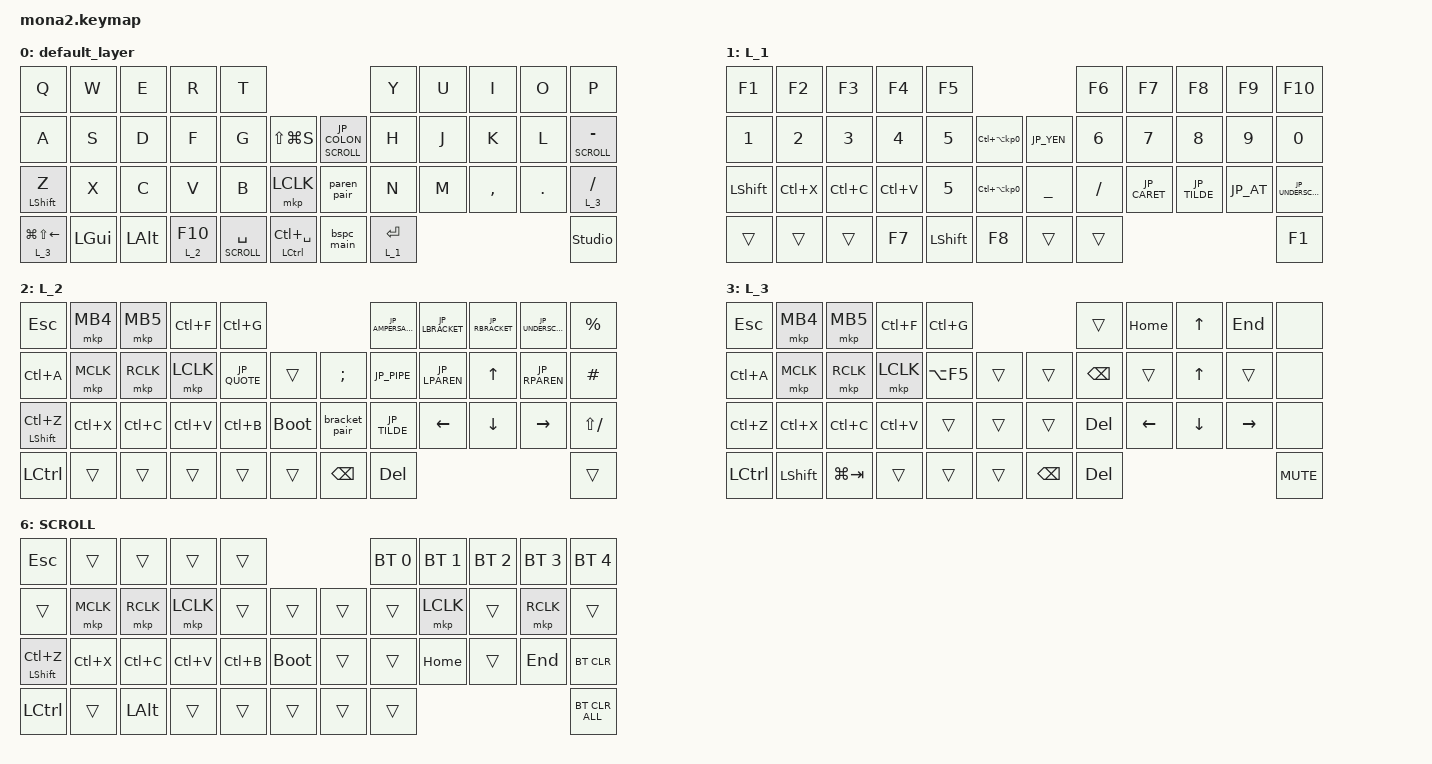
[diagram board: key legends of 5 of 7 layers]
#include <behaviors.dtsi>
#include <dt-bindings/zmk/bt.h>
#include <dt-bindings/zmk/keys.h>
#include <dt-bindings/zmk/pointing.h>
#include <dt-bindings/zmk/input_transform.h>
//#include <dt-bindings/zmk/studio_unlock.h>

/* レイヤー番号の定義：&lt や &mo で使う名前を数値に紐付けます */
#define L_BASE 0
#define L_1    1
#define L_2    2
#define L_3    3
#define L_4    4
#define MOUSE  5
#define SCROLL 6

// --- 日本語キーボード用の定義（全角スペース等のゴミを除去） ---
#define JP_DQUOTE      AT
#define JP_AMPERSAND   CARET
#define JP_QUOTE       AMPERSAND
#define JP_EQUAL       UNDER
#define JP_CARET       EQUAL
#define JP_YEN         0x89
#define JP_PLUS        COLON
#define JP_TILDE       PLUS
#define JP_PIPE        LS(0x89)
#define JP_AT          LEFT_BRACKET
#define JP_COLON       SINGLE_QUOTE
#define JP_ASTERISK    DOUBLE_QUOTES
#define JP_UNDERSCORE  LS(0x87)
#define JP_GRAVE       LS(LEFT_BRACE)
#define JP_LBRACKET    RIGHT_BRACKET
#define JP_RBRACKET    BACKSLASH
#define JP_LPAREN      ASTERISK
#define JP_RPAREN      LEFT_PARENTHESIS
#define JP_LBRACE      RIGHT_BRACE
#define JP_RBRACE      PIPE

&mt {
    flavor = "balanced";
    quick-tap-ms = <0>;
};

&lt {
    quick-tap-ms = <200>;
    flavor = "balanced";
};

/ {
    combos {
        compatible = "zmk,combos";
        tab { bindings = <&kp TAB>; key-positions = <11 12>; };
        shift_tab { bindings = <&kp LS(TAB)>; key-positions = <12 13>; };
        esc { bindings = <&kp ESC>; key-positions = <0 1>; };
        double_quotation { bindings = <&kp DOUBLE_QUOTES>; key-positions = <20 21>; };
        eq { bindings = <&kp EQUAL>; key-positions = <24 25>; };
    };

    macros {
        to_layer_0: to_layer_0 {
            compatible = "zmk,behavior-macro-one-param";
            #binding-cells = <1>;
            bindings = <&to 0 &macro_param_1to1 &kp MACRO_PLACEHOLDER>;
            label = "TO_LAYER_0";
        };

        paren_pair: paren_pair {
            compatible = "zmk,behavior-macro";
            #binding-cells = <0>;
            bindings = <&macro_tap &kp LS(NUMBER_8) &kp LS(NUMBER_9) &kp LEFT>;
        };
        
        bracket_pair: bracket_pair {
            compatible = "zmk,behavior-macro";
            #binding-cells = <0>;
            bindings = <&macro_tap &kp JP_LBRACKET &kp JP_RBRACKET &kp LEFT>;
        };
    };

    behaviors {
        lt_to_layer_0: lt_to_layer_0 {
            compatible = "zmk,behavior-hold-tap";
            label = "LAYER_TAP_TO_0";
            bindings = <&mo>, <&to_layer_0>;
            #binding-cells = <2>;
            tapping-term-ms = <200>;
        };

        scroll_up_down: mouse_wheel_up_down {
            compatible = "zmk,behavior-sensor-rotate";
            #sensor-binding-cells = <0>;
            bindings = <&msc SCRL_DOWN>, <&msc SCRL_UP>;
            tap-ms = <20>;
        };

        scroll_right_left: mouse_wheel_right_left {
            compatible = "zmk,behavior-sensor-rotate";
            #sensor-binding-cells = <0>;
            bindings = <&msc SCRL_LEFT>, <&msc SCRL_RIGHT>;
            tap-ms = <20>;
        };

        // DYA Studio対応: ランタイム回転
        rsr_vol: rsr_vol {
            compatible = "zmk,behavior-sensor-rotate";
            #sensor-binding-cells = <0>;
            bindings = <&kp C_VOL_DN>, <&kp C_VOL_UP>;
            tap-ms = <20>;
        };

                // バックスペースのTap-Dance（最新仕様）
        bspc_main: bspc_main {
            compatible = "zmk,behavior-tap-dance";
            #binding-cells = <0>;
            tapping-term-ms = <170>;
            bindings = <&bspc_single LSHFT BSPC>, <&bspc_repeat_hold 0 BSPC>;
        };

        bspc_single: bspc_single {
            compatible = "zmk,behavior-hold-tap";
            #binding-cells = <2>;
            flavor = "tap-preferred";
            tapping-term-ms = <200>;
            quick-tap-ms = <125>;
            bindings = <&kp>, <&kp>;
        };

        bspc_repeat_hold: bspc_repeat_hold {
            compatible = "zmk,behavior-hold-tap";
            #binding-cells = <2>;
            flavor = "tap-preferred";
            tapping-term-ms = <30>;
            bindings = <&bspc_macro>, <&kp>;
        };

        bspc_macro: bspc_macro {
            compatible = "zmk,behavior-macro";
            #binding-cells = <0>;
            bindings = <&macro_press &kp BSPC>, <&macro_pause_for_release>, <&macro_release &kp BSPC>;
        };

    };

    keymap {
        compatible = "zmk,keymap";

        default_layer {
            bindings = <
&kp Q               &kp W            &kp E               &kp R               &kp T                                                                                                    &kp Y                   &kp U                   &kp I                &kp O            &kp P
&kp A               &kp S            &kp D               &kp F               &kp G                            &kp LS(LG(S))                &lt SCROLL JP_COLON                    &kp H                   &kp J                   &kp K                &kp L            &lt SCROLL MINUS
&mt LEFT_SHIFT Z    &kp X            &kp C               &kp V               &kp B                            &mkp LCLK                    &paren_pair                         &kp N                   &kp M                   &kp COMMA            &kp DOT          &lt L_3 SLASH
&lt L_3 LG(LS(LEFT_ARROW)) &kp LEFT_GUI &kp LEFT_ALT     &lt L_2 F10         &lt SCROLL SPACE           &mt LEFT_CONTROL LC(SPACE)  &bspc_main   &lt L_1 ENTER                                                                                                         &studio_unlock
        >;
            sensor-bindings = <&rsr_vol>;
        };

        L_1 {
            bindings = <
&kp F1                      &kp F2           &kp F3           &kp F4           &kp F5                                                      &kp F6        &kp F7             &kp F8          &kp F9           &kp F10
&kp NUMBER_1      &kp NUMBER_2     &kp NUMBER_3     &kp NUMBER_4     &kp NUMBER_5    &kp LC(LA(KP_NUMBER_0))      &kp JP_YEN  &kp NUMBER_6  &kp NUMBER_7       &kp NUMBER_8    &kp NUMBER_9     &kp NUMBER_0
&kp LEFT_SHIFT    &kp LC(X)        &kp LC(C)        &kp LC(V)        &kp NUMBER_5    &kp LC(LA(KP_NUMBER_0))      &kp UNDERSCORE  &kp SLASH  &kp JP_CARET       &kp JP_TILDE     &kp JP_AT       &kp JP_UNDERSCORE
&trans            &trans           &trans           &kp F7           &kp LEFT_SHIFT  &kp F8                       &trans             &trans                                                      &kp F1
            >;
            sensor-bindings = <&scroll_right_left>;
        };

        L_2 {
            bindings = <
&kp ESC                &mkp MB4        &mkp MB5          &kp LC(F)      &kp LC(G)                                     &kp JP_AMPERSAND  &kp JP_LBRACKET  &kp JP_RBRACKET  &kp JP_UNDERSCORE  &kp PERCENT
&kp LC(A)              &mkp MCLK       &mkp RCLK         &mkp LCLK      &kp JP_QUOTE    &trans      &kp SEMICOLON     &kp JP_PIPE       &kp JP_LPAREN    &kp UP_ARROW     &kp JP_RPAREN       &kp HASH
&mt LEFT_SHIFT LC(Z)   &kp LC(X)       &kp LC(C)         &kp LC(V)      &kp LC(B)       &bootloader      &bracket_pair  &kp JP_TILDE      &kp LEFT_ARROW   &kp DOWN_ARROW   &kp RIGHT_ARROW    &kp LS(SLASH)
&kp LEFT_CONTROL       &trans          &trans            &trans         &trans          &trans      &kp BSPC             &kp DEL                                                                 &trans
            >;
            sensor-bindings = <&scroll_up_down>;
        };

        L_3 {
            bindings = <
&kp ESC           &mkp MB4     &mkp MB5     &kp LC(F)   &kp LC(G)                               &trans         &kp HOME         &kp UP_ARROW     &kp END           &none
&kp LC(A)         &mkp MCLK    &mkp RCLK    &mkp LCLK   &kp LA(F5)  &trans      &trans        &kp BSPC  &trans           &kp UP_ARROW     &trans   &none
&kp LC(Z)         &kp LC(X)    &kp LC(C)    &kp LC(V)   &trans      &trans      &trans        &kp DEL        &kp LEFT_ARROW   &kp DOWN_ARROW   &kp RIGHT_ARROW   &none
&kp LEFT_CONTROL  &kp LEFT_SHIFT  &kp LG(TAB)  &trans   &trans      &trans      &kp BSPC  &kp DEL                                                             &kp K_MUTE
            >;
            sensor-bindings = <&rsr_vol>;
        };

        L_4 {
            bindings = <
&trans  &trans  &trans  &trans  &trans                         &bt BT_SEL 0  &bt BT_SEL 1  &bt BT_SEL 2  &bt BT_SEL 3  &bt BT_SEL 4
&trans  &trans  &trans  &trans  &trans                &trans   &trans        &trans        &trans        &trans        &trans
&trans  &trans  &trans  &trans  &trans  &trans    &bootloader  &trans        &trans        &trans        &trans        &bt BT_CLR
&trans  &trans  &trans  &trans  &trans  &trans    &trans       &trans                                                  &bt BT_CLR_ALL
            >;
            sensor-bindings = <&scroll_up_down>;
        };

        MOUSE {
            bindings = <
&trans  &trans    &trans    &trans    &trans                    &trans  &trans    &trans    &trans    &trans
&trans  &mkp MB3  &mkp MB2  &mkp MB1  &trans            &trans  &trans  &mkp MB1  &mkp MB2  &mkp MB3  &trans
&trans  &trans    &trans    &trans    &trans  &trans    &trans  &trans  &trans    &trans    &trans    &trans
&trans  &trans    &trans    &trans    &trans  &trans    &trans  &trans                                &trans
            >;
            sensor-bindings = <&scroll_up_down>;
        };

        SCROLL {
            bindings = <
&kp ESC               &trans        &trans        &trans        &trans                                &bt BT_SEL 0  &bt BT_SEL 1  &bt BT_SEL 2  &bt BT_SEL 3  &bt BT_SEL 4
&trans                &mkp MCLK     &mkp RCLK     &mkp LCLK     &trans      &trans       &trans       &trans        &mkp LCLK        &trans        &mkp RCLK        &trans
&mt LEFT_SHIFT LC(Z)   &kp LC(X)    &kp LC(C)     &kp LC(V)     &kp LC(B)   &bootloader  &trans       &trans        &kp HOME      &trans     &kp END        &bt BT_CLR
&kp LEFT_CONTROL      &trans        &kp LEFT_ALT  &trans        &trans      &trans       &trans       &trans                                                  &bt BT_CLR_ALL
            >;
            sensor-bindings = <&scroll_up_down>;
        };
    };
};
